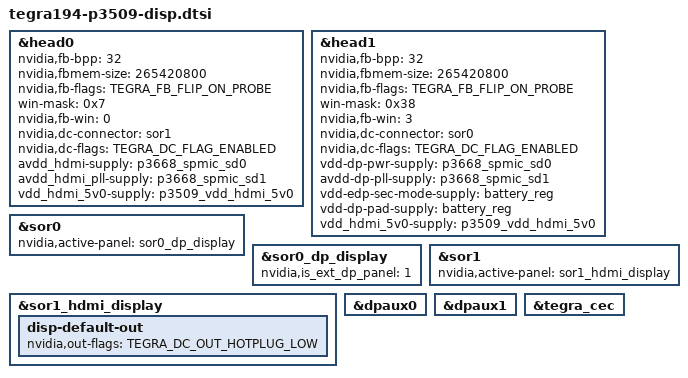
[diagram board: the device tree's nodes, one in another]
/*
 * tegra194-p3509-disp.dtsi:
 *
 * Copyright (c) 2019, NVIDIA CORPORATION.  All rights reserved.
 *
 * This program is free software; you can redistribute it and/or modify
 * it under the terms of the GNU General Public License as published by
 * the Free Software Foundation; version 2 of the License.
 *
 * This program is distributed in the hope that it will be useful, but WITHOUT
 * ANY WARRANTY; without even the implied warranty of MERCHANTABILITY or
 * FITNESS FOR A PARTICULAR PURPOSE.  See the GNU General Public License for
 * more details.
 *
 *
 * t194 jakku product uses 2 display heads out of the 4 available on t194:
 *	fb0: Head0->SOR1->HDMI
 *	fb1: Head1->SOR0->DP
 * Each display head is assigned three windows each.
 */

#include <dt-bindings/display/tegra-dc.h>
#include <dt-bindings/display/tegra-panel.h>
#include <t19x-common-platforms/tegra194-hdmi.dtsi>
#include <t19x-common-platforms/tegra194-dp.dtsi>
#include "tegra194-fixed-regulator-p3509-0000-a00.dtsi"
#include "tegra194-spmic-p3668.dtsi"

&head0 {
	status = "okay";
	nvidia,fb-bpp = <32>;
	nvidia,fbmem-size = <265420800>; /* 8K (7680*4320) 32bpp double buffered */
	nvidia,fb-flags = <TEGRA_FB_FLIP_ON_PROBE>;
	win-mask = <0x7>;
	nvidia,fb-win = <0>;
	nvidia,dc-connector = <&sor1>;
	nvidia,dc-flags = <TEGRA_DC_FLAG_ENABLED>;
	avdd_hdmi-supply = <&p3668_spmic_sd0>; /* 1v0 */
	avdd_hdmi_pll-supply = <&p3668_spmic_sd1>; /* 1v8 */
	vdd_hdmi_5v0-supply = <&p3509_vdd_hdmi_5v0>; /* 5v0 */
};

&head1 {
	status = "okay";
	nvidia,fb-bpp = <32>;
	nvidia,fbmem-size = <265420800>; /* 8K (7680*4320) 32bpp double buffered */
	nvidia,fb-flags = <TEGRA_FB_FLIP_ON_PROBE>;
	win-mask = <0x38>;
	nvidia,fb-win = <3>;
	nvidia,dc-connector = <&sor0>;
	nvidia,dc-flags = <TEGRA_DC_FLAG_ENABLED>;
	vdd-dp-pwr-supply = <&p3668_spmic_sd0>;
	avdd-dp-pll-supply = <&p3668_spmic_sd1>;
	vdd-edp-sec-mode-supply = <&battery_reg>;
	vdd-dp-pad-supply = <&battery_reg>;
	vdd_hdmi_5v0-supply = <&p3509_vdd_hdmi_5v0>;
};

&sor0 {
	status = "okay";
	nvidia,active-panel = <&sor0_dp_display>;
};

&sor0_dp_display {
	status = "okay";
	nvidia,is_ext_dp_panel = <1>;
};

&sor1 {
	status = "okay";
	nvidia,active-panel = <&sor1_hdmi_display>;
};

&sor1_hdmi_display {
	status = "okay";
	disp-default-out {
		nvidia,out-flags = <TEGRA_DC_OUT_HOTPLUG_LOW>;
	};
};

&dpaux0 {
	status = "okay";
};

&dpaux1 {
	status = "okay";
};

&tegra_cec {
	status = "okay";
};
